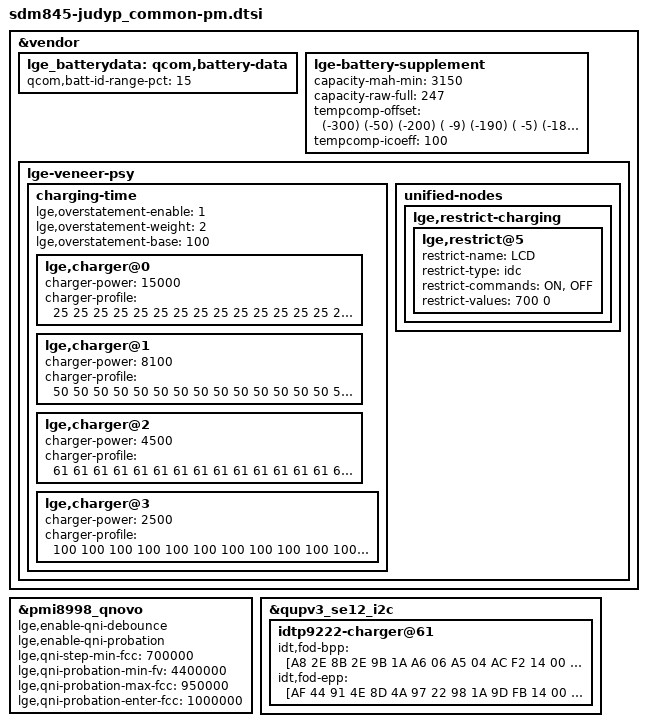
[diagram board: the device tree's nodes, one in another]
/* Copyright (c) 2017, The Linux Foundation. All rights reserved.
 *
 * This program is free software; you can redistribute it and/or modify
 * it under the terms of the GNU General Public License version 2 and
 * only version 2 as published by the Free Software Foundation.
 *
 * This program is distributed in the hope that it will be useful,
 * but WITHOUT ANY WARRANTY; without even the implied warranty of
 * MERCHANTABILITY or FITNESS FOR A PARTICULAR PURPOSE.  See the
 * GNU General Public License for more details.
 */

#include "../sdm845-judy_common/sdm845-judy_common-pm.dtsi"

&vendor {
	lge_batterydata: qcom,battery-data {
		qcom,batt-id-range-pct = <15>;

		#include "../../sdm845-battery/LGE_NEO_TEMP_3000mah.dtsi"
		#include "../../sdm845-battery/LGE_BLT37_QDM_3000mAh.dtsi"
		#include "../../sdm845-battery/LGE_BLT37_QDM_2410mAh.dtsi"
		#include "../../sdm845-battery/LGE_BLT34_LGC_3300mAh.dtsi"
	};

	lge-battery-supplement {
		capacity-mah-min = <3150>;
		capacity-raw-full = <247>;

		/* format : (temp index) (temp delta) */
		tempcomp-offset = <
			(-300) (-50)
			(-200) ( -9)
			(-190) ( -5)
			(-180)    0
			(-170)    5
			(-160)   10
			(-150)   12
			(-100)   27
			(-50)    35
			0        37
			50       25
			100      22
			150      14
			200       4
			250    ( -7)
			300    (-19)
			350    (-30)
			400    (-36)
			450    (-44)
			500    (-64)
			550    (-36)
			600    (-31)
			700    (-10)
			800    (-10)
			900    (-10)
		>;
		tempcomp-icoeff = <100>;
	};

	lge-veneer-psy {
		charging-time {
			#address-cells = <1>;
			#size-cells = <0>;

			lge,overstatement-enable = <1>;
			lge,overstatement-weight = <2>;
			lge,overstatement-base = <100>;

			lge,charger@0 {		//  fast charger: 9000mV * 1660mA or 5000mV * 3000mA
				charger-power = <15000>;
				charger-profile = <
					 25  25  25  25  25  25  25  25  25  25  25  25  25  25  25  25
					 25  25  25  25  25  25  25  25  25  25  25  25  25  25  25  25
					 25  25  25  25  25  25  25  25  25  25  25  25  25  25  25  25
					 25  25  25  25  25  25  25  25  25  25  25  25  25  25  25  25
					 25  25  25  25  25  25  25  25  25  25  25  25  25  25  25  25
					 25  25  25  25  25  25  25  25  25  25  25  25  25  25  25  25
					 25  25  25  25  25  25  25  25  25  25  25  25  25  25  25  25
					 25  25  25  25  25  25  25  25  25  25  25  25  25  25  25  25
					 25  25  25  25  25  25  25  25  25  25  25  25  25  25  25  25
					 25  25  25  25  25  25  25  25  25  25  25  25  25  25  25  25
					 25  25  25  25  25  25  25  25  25  25  25  25  25  25  25  25
					 25  25  25  25  25  25  25  25  25  25  25  25  25  25  25  25
					 25  25  25  25  25  25  25  25  25  25  25  25  25  25  25  25
					 25  25  25  25  25  25  25  25  25  25  25  25  25  25  25  25
					 25  25  25  25  25  25  25  25  25  25  25  25  25  25  25  25
					 25  25  25  25  25  25  25  25  25  25  25  25  25  25  25  25
				>;
			};
			lge,charger@1 {		// EPP wireless charger: 9000mV * 900mA = 8.1W
				charger-power = <8100>;
				charger-profile = <
					 50  50  50  50  50  50  50  50  50  50  50  50  50  50  50  50
					 50  50  50  50  50  50  50  50  50  50  50  50  50  50  50  50
					 50  50  50  50  50  50  50  50  50  50  50  50  50  50  50  50
					 50  50  50  50  50  50  50  50  50  50  50  50  50  50  50  50
					 50  50  50  50  50  50  50  50  50  50  50  50  50  50  50  50
					 50  50  50  50  50  50  50  50  50  50  50  50  50  50  50  50
					 50  50  50  50  50  50  50  50  50  50  50  50  50  50  50  50
					 50  50  50  50  50  50  50  50  50  50  50  50  50  50  50  50
					 50  50  50  50  50  50  50  50  50  50  50  50  50  50  50  50
					 50  50  50  50  50  50  50  50  50  50  50  50  50  50  50  50
					 50  50  50  50  50  50  50  50  50  50  50  50  50  50  50  50
					 50  50  50  50  50  50  50  50  50  50  50  50  50  50  50  50
					 50  50  50  50  50  50  50  50  50  50  50  50  50  50  50  50
					 50  50  50  50  50  50  50  50  50  50  50  50  50  50  50  50
					 50  50  50  50  50  50  50  50  50  50  50  50  50  50  50  50
					 50  50  50  50  50  50  50  50  50  50  50  50  50  50  50  50
				>;
			};
			lge,charger@2 {		// BPP wireless charger: 5000mV * 900mA = 4.5W
				charger-power = <4500>;
				charger-profile = <
					 61  61  61  61  61  61  61  61  61  61  61  61  61  61  61  61
					 61  61  61  61  61  61  61  61  61  61  61  61  61  61  61  61
					 61  61  61  61  61  61  61  61  61  61  61  61  61  61  61  61
					 61  61  61  61  61  61  61  61  61  61  61  61  61  61  61  61
					 61  61  61  61  61  61  61  61  61  61  61  61  61  61  61  61
					 61  61  61  61  61  61  61  61  61  61  61  61  61  61  61  61
					 61  61  61  61  61  61  61  61  61  61  61  61  61  61  61  61
					 61  61  61  61  61  61  61  61  61  61  61  61  61  61  61  61
					 61  61  61  61  61  61  61  61  61  61  61  61  61  61  61  61
					 61  61  61  61  61  61  61  61  61  61  61  61  61  61  61  61
					 61  61  61  61  61  61  61  61  61  61  61  61  61  61  61  61
					 61  61  61  61  61  61  61  61  61  61  61  61  61  61  61  61
					 61  61  61  61  61  61  61  61  61  61  61  61  61  61  61  61
					 61  61  61  61  61  61  61  61  61  61  61  61  61  61  61  61
					 61  61  61  61  61  61  61  61  61  61  61  61  61  61  61  61
					 61  61  61  61  61  61  61  61  61  61  61  61  61  61  61  61
				>;
			};
			lge,charger@3 {		// SDP: 5000mV * 500mA = 2.5W
				charger-power = <2500>;
				charger-profile = <
					100 100 100 100 100 100 100 100 100 100 100 100 100 100 100 100
					100 100 100 100 100 100 100 100 100 100 100 100 100 100 100 100
					100 100 100 100 100 100 100 100 100 100 100 100 100 100 100 100
					100 100 100 100 100 100 100 100 100 100 100 100 100 100 100 100
					100 100 100 100 100 100 100 100 100 100 100 100 100 100 100 100
					100 100 100 100 100 100 100 100 100 100 100 100 100 100 100 100
					100 100 100 100 100 100 100 100 100 100 100 100 100 100 100 100
					100 100 100 100 100 100 100 100 100 100 100 100 100 100 100 100
					100 100 100 100 100 100 100 100 100 100 100 100 100 100 100 100
					100 100 100 100 100 100 100 100 100 100 100 100 100 100 100 100
					100 100 100 100 100 100 100 100 100 100 100 100 100 100 100 100
					100 100 100 100 100 100 100 100 100 100 100 100 100 100 100 100
					100 100 100 100 100 100 100 100 100 100 100 100 100 100 100 100
					100 100 100 100 100 100 100 100 100 100 100 100 100 100 100 100
					100 100 100 100 100 100 100 100 100 100 100 100 100 100 100 100
					100 100 100 100 100 100 100 100 100 100 100 100 100 100 100 100
				>;
			};
		};

		unified-nodes {
			lge,restrict-charging {
				lge,restrict@5 {
					restrict-name = "LCD";
					restrict-type = "idc";
					restrict-commands = "ON", "OFF";
					restrict-values = < 700      0>;
				};
			};
		};
	};
};

&pmi8998_qnovo {
	lge,enable-qni-debounce;

	lge,enable-qni-probation;
	lge,qni-step-min-fcc = <700000>;
	lge,qni-probation-min-fv = <4400000>;
	lge,qni-probation-max-fcc = <950000>;
	lge,qni-probation-enter-fcc = <1000000>;
};

&qupv3_se12_i2c {
	idtp9222-charger@61 {
		// FOD parameters
		idt,fod-bpp = [A8 2E 8B 2E 9B 1A A6 06 A5 04 AC F2 14 00 00 00];
		idt,fod-epp = [AF 44 91 4E 8D 4A 97 22 98 1A 9D FB 14 00 64 32];
	};
};

